# RL6955_IP_SVD register map
Vendor: Realtek
Registers are 32-bit, read-write, reset 0x0 unless marked. A register's access mark holds for its fields unless they carry their own. Offsets are from the block's base; [hi:lo] are bit positions; {n}, {i} and the like mark numbered series; 'fields as' and 'values as' point back to an identical list.

## RXI300_REG_P1
Base 0x400C6000
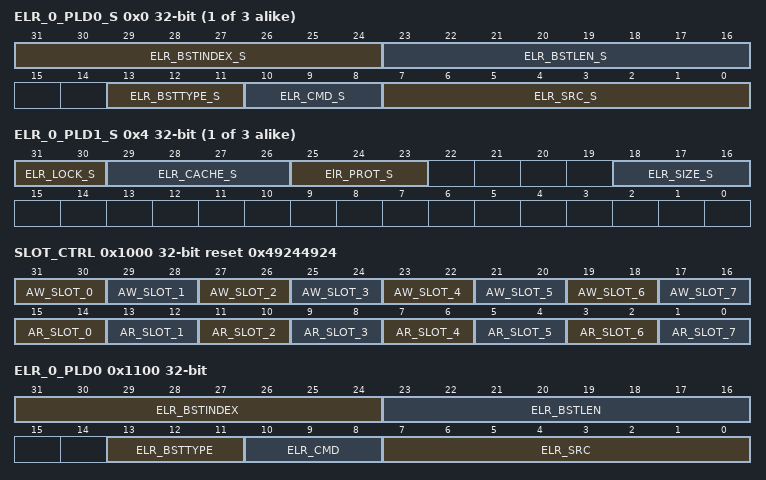
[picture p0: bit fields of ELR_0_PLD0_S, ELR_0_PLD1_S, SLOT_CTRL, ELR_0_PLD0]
{0x0+0x40*i} ELR_{i}_PLD0_S ro (i=0..2) — Error log payload register0
  [31:24] ELR_BSTINDEX_S — Burst index of the error request.
  [23:16] ELR_BSTLEN_S — Burst Length of the error request.
  [13:11] ELR_BSTTYPE_S — BurstSeq of the error request.
  [10:8] ELR_CMD_S — CMD of the error request. 0x1: Write command 0x2: Read command
  [7:0] ELR_SRC_S — Error source of the error request. 0x20: M0,M8,M10 access p1s0-0 secure default 0x21: M0,M8,M10 access p1s0-1~p1s0-4 secure default 0x22: M0,M8,M10 access p1s0-5~p1s0-6 secure default 0x11: M0,M8,M10 access p1s0-7~p1s0-8 secure default 0x10: M0,M8,M10 access p1s1-0~p1s1-6 secure default
{0x4+0x40*i} ELR_{i}_PLD1_S ro (i=0..2) — Error log payload register1
  [31:30] ELR_LOCK_S — AxLock of the error request.
  [29:26] ELR_CACHE_S — AxCache of the error request.
  [25:23] ElR_PROT_S — AxProt of the error request.
  [18:16] ELR_SIZE_S — Size of the error request.
{0x8+0x40*i} ELR_{i}_ID_S ro (i=0..2) — Error log ID information register
  [31:0] ELR_ID_S — Tagid of the error request. 8'b0000????: M0 KM4TZ security error 8'b1101????: M8 KM4NS security error 8'b1111????: M10 OTPC/SIC access error
{0xC+0x40*i} ELR_{i}_ADR0_S ro (i=0..2) — Error log addrress register0
  [31:0] ELR_ADR0_S — Address[31:0] of the error request.
{0x10+0x40*i} ELR_{i}_ADR1_S ro (i=0..2) — Error log addrress register1
  [63:32] ELR_ADR1_S — Address[63:32] of the error request.
{0x30+0x40*i} ELR_{i}_CODE_S ro (i=0..2) — Error code register
  [7:0] ELR_CODE_S — The error code of error request, if it's 0, indicates that there is no error request. 8'h00: No error 8'h02: Secure fault error
{0x3C+0x40*i} ELR_{i}_INTR_CLR_S wo (i=0..2) — Error log clear register
  [0] ELR_INTR_CLR_S — Error log interrupt clear. Writing 1'b1 to the register will trigger a 1-cycle pulse interrupt clear. It has to write 1'b1 to this register every time when the error exception occurs. Note that this register is write-only, the return value of reading this register is meaningless.
0x1000 SLOT_CTRL reset 0x49244924 — Slot control of weighted round-robin for SRAM
  [31-2n:30-2n] AW_SLOT_{n} (n=0..7) — Control value of write slot {n}
  [15-2n:14-2n] AR_SLOT_{n} (n=0..7) — Control value of read slot {n}
0x1100 ELR_0_PLD0 ro — Error log payload register0
  [31:24] ELR_BSTINDEX — Burst index of the error request.
  [23:16] ELR_BSTLEN — Burst Length of the error request.
  [13:11] ELR_BSTTYPE — BurstSeq of the error request.
  [10:8] ELR_CMD — CMD of the error request. 0x1: Write command 0x2: Read command
  [7:0] ELR_SRC — Error source of the error request. 0x00: km4ns or otpc address hole default slave 0x24: wifi or aes_sha address hole default slave
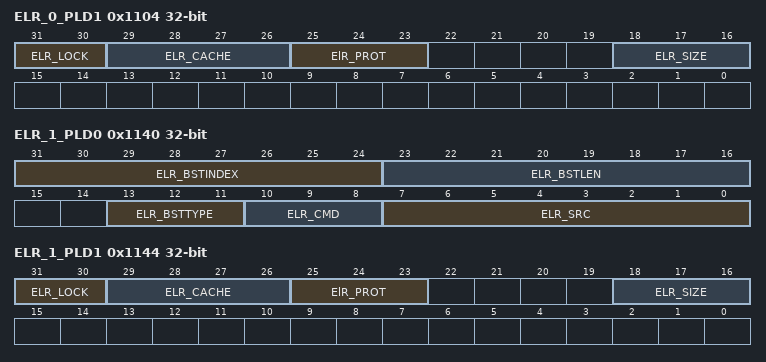
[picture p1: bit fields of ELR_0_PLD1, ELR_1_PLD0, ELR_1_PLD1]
0x1104 ELR_0_PLD1 ro — Error log payload register1
  [31:30] ELR_LOCK — AxLock of the error request.
  [29:26] ELR_CACHE — AxCache of the error request.
  [25:23] ElR_PROT — AxProt of the error request.
  [18:16] ELR_SIZE — Size of the error request.
0x110C ELR_0_ADR0 ro — Error log addrress register0
  [31:0] ELR_ADR0 — Address[31:0] of the error request.
0x1110 ELR_0_ADR1 ro — Error log addrress register1
  [63:32] ELR_ADR1 — Address[63:32] of the error request.
0x1130 ELR_0_CODE ro — Error code register
  [7:0] ELR_CODE — The error code of error request, if it's 0, indicates that there is no error request. 8'h00: No error 8'h01: Address hole error
0x113C ELR_0_INTR_CLR wo — Error log clear register
  [0] ELR_INTR_CLR — Error log interrupt clear. Writing 1'b1 to the register will trigger a 1-cycle pulse interrupt clear. It has to write 1'b1 to this register every time when the error exception occurs. Note that this register is write-only, the return value of reading this register is meaningless.
0x1140 ELR_1_PLD0 ro — Error log payload register0
  fields as ELR_0_PLD0
0x1144 ELR_1_PLD1 ro — Error log payload register1
  fields as ELR_0_PLD1
0x1148 ELR_0_ID ro — Error log ID information register
  [31:0] ELR_ID — Tagid of the error request. 8'b0000????: M0 KM4TZaccess error 8'b1101????: M8 KM4NS access error 8'b1111????: M10 OTPC/SIC access error 8'b101?????: M11 AES_SHA access error 8'b1110????: M9 WIFI access error
0x114C ELR_1_ADR0 ro — Error log addrress register0
  [31:0] ELR_ADR0 — Address[31:0] of the error request.
0x1150 ELR_1_ADR1 ro — Error log addrress register1
  [63:32] ELR_ADR1 — Address[63:32] of the error request.
0x1170 ELR_1_CODE ro — Error code register
  fields as ELR_0_CODE
0x117C ELR_1_INTR_CLR wo — Error log clear register
  fields as ELR_0_INTR_CLR
0x1200 NAME ro reset 0x52300 — RXI300 design name register
  [31:0] NAME — The design name of RXI-300.
0x1204 VER ro reset 0x300 — RXI300 design version register
  [31:0] VER — The design version of RXI-300.
0x1208 RVE ro — RXI300 design reversion register
  [31:0] REV — The design reversion of RXI-300.
0x120C INST ro — RXI300 design instance number register
  [31:0] INST — The design instance number of RXI-300.
0x1210 IMPL_Y ro reset 0x2025 — RXI300 implementation year register
  [31:0] IMPL_Y — The implementatin year of RXI-300. Reset value depends on implementation date.
0x1214 IMPL_D ro reset 0x3131449 — RXI300 implementation date register
  [31:0] IMPL_D — The implementatin date of RXI-300. Reset value depends on implementation date.
0x1218 DEV ro reset 0x522734 — RXI300 developer register
  [31:0] DEV — The developer of RXI-300.
0x121C PRO_NUM ro reset 0x6955 — RXI300 project number register
  [31:0] PRO_NUM — The project number of RXI-300.
